AUTOSAR XML (schema 4.0)
standard types defined: float32, float64, sint16, sint32, sint8, uint16, uint32, uint8, void, boolean
package /ImplDataTypes
  impl type MultiStateBtnType: implementation-data-type=uint8, type-emitter=RTE
package /MappingSets
  data type mapping set MappingSet
package /PortInterfaces/SenderReceiver
  sender receiver interface SrIf_SeatCtrlBtns
    data DE_HeightBtnState: type=MultiStateBtnType
    data DE_InclineBtnState: type=MultiStateBtnType
    data DE_SlideBtnState: type=MultiStateBtnType
  sender receiver interface SrIf_SeatCtrlData
    data DE_Height: type=uint8
    data DE_Incline: type=uint8
    data DE_Slide: type=uint8
package /SoftwareComponents
  swc implementation Impl_SWC_ECU1: programming-language=C, sw-version=1.0.0, vendor-id=255, behavior=Ibhv_SWC_ECU1
    code-descriptors:
      code Code: artifact-descriptors=autosar-engineering-object={short-label=SWC.c, category=SWSRC}
    resource consumption ResourceConsumption
  swc implementation Impl_SWC_HMI: programming-language=C, sw-version=1.0.0, vendor-id=255, behavior=Ibhv_SWC_HMI
    code-descriptors:
      code Code: artifact-descriptors=autosar-engineering-object={short-label=SWC.c, category=SWSRC}
    resource consumption ResourceConsumption
  swc implementation Impl_SWC_SeatMgr: programming-language=C, sw-version=1.0.0, vendor-id=255, behavior=Ibhv_SWC_SeatMgr
    code-descriptors:
      code Code: artifact-descriptors=autosar-engineering-object={short-label=SWC.c, category=SWSRC}
    resource consumption ResourceConsumption
  application sw component type SWC_ECU1
    provide port pp_SeatCtrlData: provided-interface=SrIf_SeatCtrlData
    behavior Ibhv_SWC_ECU1: data-type-mapping=MappingSet, handle-termination-and-restart=NO-SUPPORT
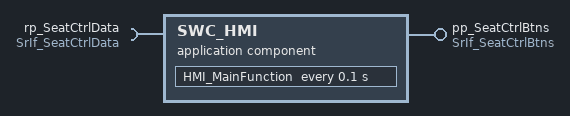
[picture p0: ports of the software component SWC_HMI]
  application sw component type SWC_HMI
    provide port pp_SeatCtrlBtns: provided-interface=SrIf_SeatCtrlBtns
    require port rp_SeatCtrlData: required-interface=SrIf_SeatCtrlData
    behavior Ibhv_SWC_HMI: data-type-mapping=MappingSet, handle-termination-and-restart=NO-SUPPORT
      timing event TE_HMI_MainFunction_100ms: start-on-event=HMI_MainFunction, period=0.1
      runnable HMI_MainFunction
        data-receive-point-by-arguments:
          access DRP_rp_SeatCtrlData_DE_Height: accessed-variable=rp_SeatCtrlData.DE_Height
          access DRP_rp_SeatCtrlData_DE_Incline: accessed-variable=rp_SeatCtrlData.DE_Incline
          access DRP_rp_SeatCtrlData_DE_Slide: accessed-variable=rp_SeatCtrlData.DE_Slide
        data-send-points:
          access DSP_pp_SeatCtrlBtns_DE_HeightBtnState: accessed-variable=pp_SeatCtrlBtns.DE_HeightBtnState
          access DSP_pp_SeatCtrlBtns_DE_InclineBtnState: accessed-variable=pp_SeatCtrlBtns.DE_InclineBtnState
          access DSP_pp_SeatCtrlBtns_DE_SlideBtnState: accessed-variable=pp_SeatCtrlBtns.DE_SlideBtnState
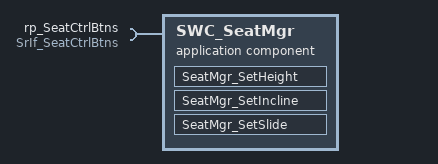
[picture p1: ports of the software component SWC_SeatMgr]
  application sw component type SWC_SeatMgr
    require port rp_SeatCtrlBtns: required-interface=SrIf_SeatCtrlBtns
    behavior Ibhv_SWC_SeatMgr: data-type-mapping=MappingSet, handle-termination-and-restart=NO-SUPPORT
      data received event DRE_rp_SeatCtrlBtns_DE_HeightBtnState: start-on-event=SeatMgr_SetHeight, data=rp_SeatCtrlBtns.DE_HeightBtnState
      data received event DRE_rp_SeatCtrlBtns_DE_InclineBtnState: start-on-event=SeatMgr_SetIncline, data=rp_SeatCtrlBtns.DE_InclineBtnState
      data received event DRE_rp_SeatCtrlBtns_DE_SlideBtnState: start-on-event=SeatMgr_SetSlide, data=rp_SeatCtrlBtns.DE_SlideBtnState
      runnable SeatMgr_SetHeight
        data-receive-point-by-arguments:
          access DRP_rp_SeatCtrlBtns_DE_HeightBtnState: accessed-variable=rp_SeatCtrlBtns.DE_HeightBtnState
      runnable SeatMgr_SetIncline
        data-receive-point-by-arguments:
          access DRP_rp_SeatCtrlBtns_DE_InclineBtnState: accessed-variable=rp_SeatCtrlBtns.DE_InclineBtnState
      runnable SeatMgr_SetSlide
        data-receive-point-by-arguments:
          access DRP_rp_SeatCtrlBtns_DE_SlideBtnState: accessed-variable=rp_SeatCtrlBtns.DE_SlideBtnState
package /Compositions
  composition sw component type SeatCtrlComposition
    component SWC_HMI: type=SWC_HMI
    component SWC_SeatMgr: type=SWC_SeatMgr
